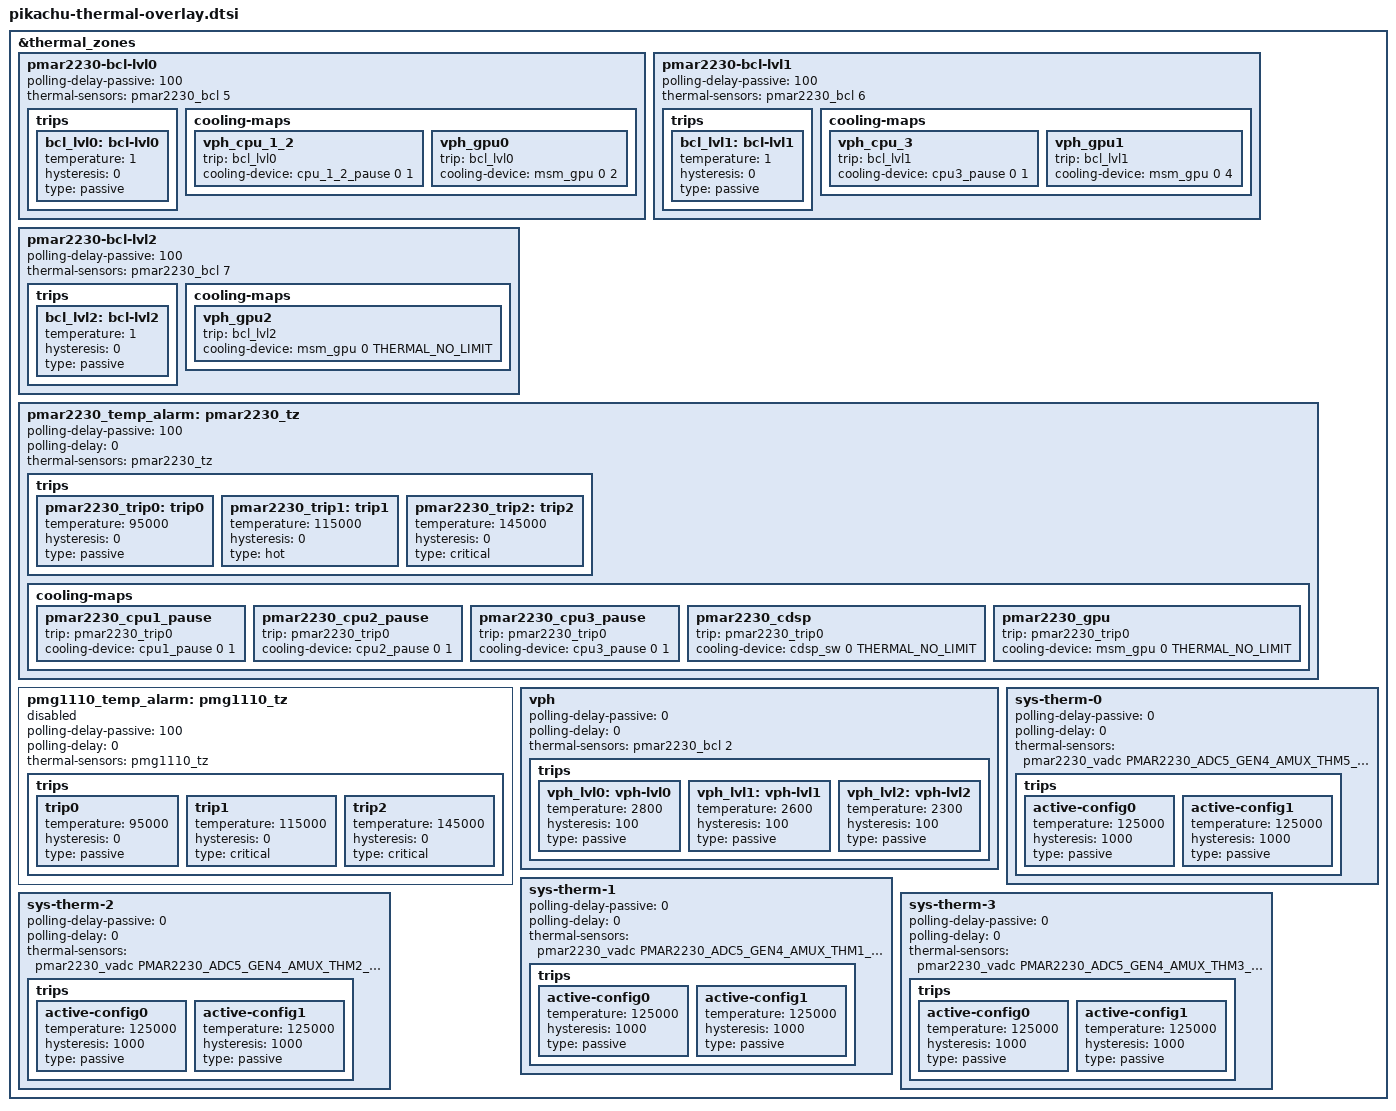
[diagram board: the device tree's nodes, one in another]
// SPDX-License-Identifier: BSD-3-Clause
/*
 * Copyright (c) Qualcomm Technologies, Inc. and/or its subsidiaries.
 */

#include <dt-bindings/thermal/thermal_qti.h>

&thermal_zones {
	pmar2230-bcl-lvl0 {
		polling-delay-passive = <100>;
		thermal-sensors = <&pmar2230_bcl 5>;

		trips {
			bcl_lvl0: bcl-lvl0 {
				temperature = <1>;
				hysteresis = <0>;
				type = "passive";
			};
		};

		cooling-maps {
			vph_cpu_1_2 {
				trip = <&bcl_lvl0>;
				cooling-device = <&cpu_1_2_pause 0 1>;
			};

			vph_gpu0 {
				trip = <&bcl_lvl0>;
				cooling-device = <&msm_gpu 0 2>;
			};
		};
	};

	pmar2230-bcl-lvl1 {
		polling-delay-passive = <100>;
		thermal-sensors = <&pmar2230_bcl 6>;

		trips {
			bcl_lvl1: bcl-lvl1 {
				temperature = <1>;
				hysteresis = <0>;
				type = "passive";
			};
		};

		cooling-maps {
			vph_cpu_3 {
				trip = <&bcl_lvl1>;
				cooling-device = <&cpu3_pause 0 1>;
			};

			vph_gpu1 {
				trip = <&bcl_lvl1>;
				cooling-device = <&msm_gpu 0 4>;
			};
		};
	};

	pmar2230-bcl-lvl2 {
		polling-delay-passive = <100>;
		thermal-sensors = <&pmar2230_bcl 7>;

		trips {
			bcl_lvl2: bcl-lvl2 {
				temperature = <1>;
				hysteresis = <0>;
				type = "passive";
			};
		};

		cooling-maps {
			vph_gpu2 {
				trip = <&bcl_lvl2>;
				cooling-device = <&msm_gpu 0 THERMAL_NO_LIMIT>;
			};
		};
	};

	pmar2230_temp_alarm: pmar2230_tz {
		polling-delay-passive = <100>;
		polling-delay = <0>;
		thermal-sensors = <&pmar2230_tz>;

		trips {
			pmar2230_trip0: trip0 {
				temperature = <95000>;
				hysteresis = <0>;
				type = "passive";
			};

			pmar2230_trip1: trip1 {
				temperature = <115000>;
				hysteresis = <0>;
				type = "hot";
			};

			pmar2230_trip2: trip2 {
				temperature = <145000>;
				hysteresis = <0>;
				type = "critical";
			};
		};

		cooling-maps {
			pmar2230_cpu1_pause {
				trip = <&pmar2230_trip0>;
				cooling-device = <&cpu1_pause 0 1>;
			};

			pmar2230_cpu2_pause {
				trip = <&pmar2230_trip0>;
				cooling-device = <&cpu2_pause 0 1>;
			};

			pmar2230_cpu3_pause {
				trip = <&pmar2230_trip0>;
				cooling-device = <&cpu3_pause 0 1>;
			};

			pmar2230_cdsp {
				trip = <&pmar2230_trip0>;
				cooling-device = <&cdsp_sw 0 THERMAL_NO_LIMIT>;
			};

			pmar2230_gpu {
				trip = <&pmar2230_trip0>;
				cooling-device = <&msm_gpu 0 THERMAL_NO_LIMIT>;
			};
		};
	};

	pmg1110_temp_alarm: pmg1110_tz {
		status = "disabled";
		polling-delay-passive = <100>;
		polling-delay = <0>;
		thermal-sensors = <&pmg1110_tz>;

		trips {
			trip0 {
				temperature = <95000>;
				hysteresis = <0>;
				type = "passive";
			};

			trip1 {
				temperature = <115000>;
				hysteresis = <0>;
				type = "critical";
			};

			trip2 {
				temperature = <145000>;
				hysteresis = <0>;
				type = "critical";
			};
		};
	};

	vph {
		polling-delay-passive = <0>;
		polling-delay = <0>;
		thermal-sensors = <&pmar2230_bcl 2>;

		trips {
			vph_lvl0:vph-lvl0 {
				temperature = <2800>;
				hysteresis = <100>;
				type = "passive";
			};

			vph_lvl1:vph-lvl1 {
				temperature = <2600>;
				hysteresis = <100>;
				type = "passive";
			};

			vph_lvl2:vph-lvl2 {
				temperature = <2300>;
				hysteresis = <100>;
				type = "passive";
			};
		};
	};

	/* XO_THERM */
	sys-therm-0 {
		polling-delay-passive = <0>;
		polling-delay = <0>;
		thermal-sensors = <&pmar2230_vadc
				   PMAR2230_ADC5_GEN4_AMUX_THM5_XO_THERM_100K_PU>;

		trips {
			active-config0 {
				temperature = <125000>;
				hysteresis = <1000>;
				type = "passive";
			};

			active-config1 {
				temperature = <125000>;
				hysteresis = <1000>;
				type = "passive";
			};
		};
	};

	/* SOC_THERM */
	sys-therm-1 {
		polling-delay-passive = <0>;
		polling-delay = <0>;
		thermal-sensors = <&pmar2230_vadc
				   PMAR2230_ADC5_GEN4_AMUX_THM1_100K_PU>;

		trips {
			active-config0 {
				temperature = <125000>;
				hysteresis = <1000>;
				type = "passive";
			};

			active-config1 {
				temperature = <125000>;
				hysteresis = <1000>;
				type = "passive";
			};
		};
	};

	/* WLAN_PA_THERM */
	sys-therm-2 {
		polling-delay-passive = <0>;
		polling-delay = <0>;
		thermal-sensors = <&pmar2230_vadc
				   PMAR2230_ADC5_GEN4_AMUX_THM2_100K_PU>;

		trips {
			active-config0 {
				temperature = <125000>;
				hysteresis = <1000>;
				type = "passive";
			};

			active-config1 {
				temperature = <125000>;
				hysteresis = <1000>;
				type = "passive";
			};
		};
	};

	/* QUIET_THERM */
	sys-therm-3 {
		polling-delay-passive = <0>;
		polling-delay = <0>;
		thermal-sensors = <&pmar2230_vadc
				   PMAR2230_ADC5_GEN4_AMUX_THM3_100K_PU>;

		trips {
			active-config0 {
				temperature = <125000>;
				hysteresis = <1000>;
				type = "passive";
			};

			active-config1 {
				temperature = <125000>;
				hysteresis = <1000>;
				type = "passive";
			};
		};
	};
};
